# ATmega162 device description
Architecture: AVR8; Family: megaAVR
Registers are 8-bit, access not given, no defined reset value unless marked. A register's access mark holds for its fields unless they carry their own. Offsets are from the block's base; [hi:lo] are bit positions.

## TC1 (TC16 module) — Timer/Counter, 16-bit
Instances: TC1 0x00
0x44 ICR1 16-bit — Timer/Counter1 Input Capture Register Bytes
0x48 OCR1B 16-bit — Timer/Counter1 Output Compare Register B Bytes
0x4A OCR1A 16-bit — Timer/Counter1 Output Compare Register A Bytes
0x4C TCNT1 16-bit — Timer/Counter1 Bytes
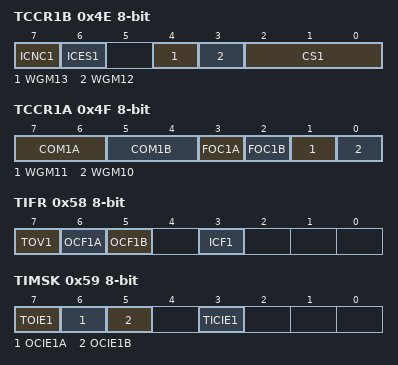
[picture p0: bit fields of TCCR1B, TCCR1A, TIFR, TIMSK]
0x4E TCCR1B — Timer/Counter1 Control Register B
  [7] ICNC1 — Input Capture 1 Noise Canceler
  [6] ICES1 — Input Capture 1 Edge Select
  [4] WGM13 (bit 2 of the value upward) — Waveform Generation Mode
  [3] WGM12 (bit 2 of the value upward) — Waveform Generation Mode
  [2:0] CS1 — Clock Select1 bits
    0=No Clock Source (Stopped); 1=Running, No Prescaling; 2=Running, CLK/8; 3=Running, CLK/64; 4=Running, CLK/256; 5=Running, CLK/1024; 6=Running, ExtClk Tx Falling Edge; 7=Running, ExtClk Tx Rising Edge
0x4F TCCR1A — Timer/Counter1 Control Register A
  [7:6] COM1A — Compare Output Mode 1A, bits
  [5:4] COM1B — Compare Output Mode 1B, bits
  [3] FOC1A — Force Output Compare for Channel A
  [2] FOC1B — Force Output Compare for Channel B
  [1] WGM11 — Waveform Generation Mode
  [0] WGM10 — Waveform Generation Mode
0x58 TIFR — Timer/Counter Interrupt Flag register
  [7] TOV1 — Timer/Counter1 Overflow Flag
  [6] OCF1A — Output Compare Flag 1A
  [5] OCF1B — Output Compare Flag 1B
  [3] ICF1 — Input Capture Flag 1
0x59 TIMSK — Timer/Counter Interrupt Mask Register
  [7] TOIE1 — Timer/Counter1 Overflow Interrupt Enable
  [6] OCIE1A — Timer/Counter1 Output CompareA Match Interrupt Enable
  [5] OCIE1B — Timer/Counter1 Output CompareB Match Interrupt Enable
  [3] TICIE1 — Timer/Counter1 Input Capture Interrupt Enable

## TC3 (TC16 module) — Timer/Counter, 16-bit
Instances: TC3 0x00
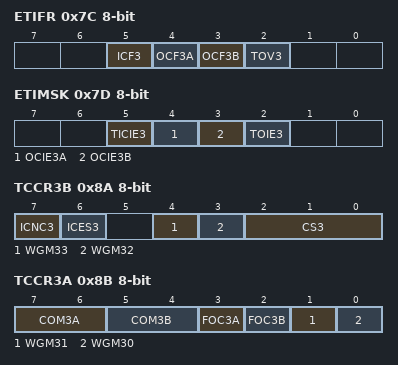
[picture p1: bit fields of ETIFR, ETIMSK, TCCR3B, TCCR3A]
0x7C ETIFR — Extended Timer/Counter Interrupt Flag register
  [5] ICF3 — Input Capture Flag 3
  [4] OCF3A — Output Compare Flag 3A
  [3] OCF3B — Output Compare Flag 3B
  [2] TOV3 — Timer/Counter3 Overflow Flag
0x7D ETIMSK — Extended Timer/Counter Interrupt Mask Register
  [5] TICIE3 — Timer/Counter3 Input Capture Interrupt Enable
  [4] OCIE3A — Timer/Counter3 Output CompareA Match Interrupt Enable
  [3] OCIE3B — Timer/Counter3 Output CompareB Match Interrupt Enable
  [2] TOIE3 — Timer/Counter3 Overflow Interrupt Enable
0x80 ICR3 16-bit — Timer/Counter3 Input Capture Register Bytes
0x84 OCR3B 16-bit — Timer/Counte3 Output Compare Register B Bytes
0x86 OCR3A 16-bit — Timer/Counter3 Output Compare Register A Bytes
0x88 TCNT3 16-bit — Timer/Counter3 Bytes
0x8A TCCR3B — Timer/Counter3 Control Register B
  [7] ICNC3 — Input Capture 3 Noise Canceler
  [6] ICES3 — Input Capture 3 Edge Select
  [4] WGM33 (bit 2 of the value upward) — Waveform Generation Mode
  [3] WGM32 (bit 2 of the value upward) — Waveform Generation Mode
  [2:0] CS3 — Clock Select3 bits
    0=No Clock Source (Stopped); 1=Running, No Prescaling; 2=Running, CLK/8; 3=Running, CLK/64; 4=Running, CLK/256; 5=Running, CLK/1024; 6=Running, CLK/16; 7=Running, CLK/32
0x8B TCCR3A — Timer/Counter3 Control Register A
  [7:6] COM3A — Compare Output Mode 3A, bits
  [5:4] COM3B — Compare Output Mode 3B, bits
  [3] FOC3A — Force Output Compare for Channel A
  [2] FOC3B — Force Output Compare for Channel B
  [1] WGM31 — Waveform Generation Mode
  [0] WGM30 — Waveform Generation Mode

## TC2 (TC8_ASYNC module) — Timer/Counter, 8-bit Async
Instances: TC2 0x00
0x42 OCR2 — Output Compare Register
0x43 TCNT2 — Timer/Counter Register
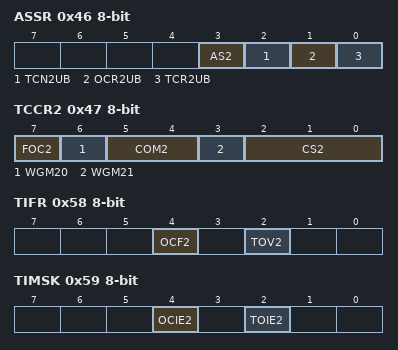
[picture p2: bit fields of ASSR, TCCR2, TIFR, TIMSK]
0x46 ASSR — Asynchronous Status Register
  [3] AS2 — Asynchronous Timer 2
  [2] TCN2UB — Timer/Counter2 Update Busy
  [1] OCR2UB — Output Compare Register2 Update Busy
  [0] TCR2UB — Timer/Counter Control Register2 Update Busy
0x47 TCCR2 — Timer/Counter Control Register
  [7] FOC2 — Forde Output Compare
  [6] WGM20 — Pulse Width Modulator Select Bit 0
    0=Normal; 2=PWM, Phase Correct; 1=CTC; 3=Fast PWM
  [5:4] COM2 — Compare Match Output Mode
  [3] WGM21 — Pulse Width Modulator Select Bit 1
  [2:0] CS2 — Clock Select
    0=No Clock Source (Stopped); 1=Running, No Prescaling; 2=Running, CLK/8; 3=Running, CLK/32; 4=Running, CLK/64; 5=Running, CLK/128; 6=Running, CLK/256; 7=Running, CLK/1024
0x58 TIFR — Timer/Counter Interrupt Flag Register
  [4] OCF2 — Output Compare Flag 2
  [2] TOV2 — Timer/Counter2 Overflow Flag
0x59 TIMSK — Timer/Counter Interrupt Mask Register
  [4] OCIE2 — Timer/Counter2 Output Compare Match Interrupt Enable
  [2] TOIE2 — Timer/Counter2 Overflow Interrupt Enable
